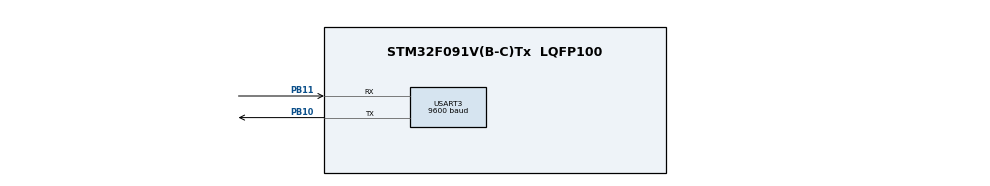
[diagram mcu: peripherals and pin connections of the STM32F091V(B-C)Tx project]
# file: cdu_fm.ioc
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Mcu.Family=STM32F0
Mcu.Name=STM32F091V(B-C)Tx
Mcu.Package=LQFP100
NVIC.USART3_8_IRQn=true\:0\:0\:false\:false\:true\:true\:true\:true
PA13.Mode=Serial_Wire
PA13.Signal=SYS_SWDIO
PA14.Mode=Serial_Wire
PA14.Signal=SYS_SWCLK
PB10.Mode=Asynchronous
PB10.Signal=USART3_TX
PB11.Mode=Asynchronous
PB11.Signal=USART3_RX
ProjectManager.HeapSize=0x200
ProjectManager.StackSize=0x400
ProjectManager.TargetToolchain=STM32CubeIDE
USART3.BaudRate=9600
USART3.VirtualMode-Asynchronous=VM_ASYNC
board=custom

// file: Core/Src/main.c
/* USER CODE BEGIN Header */
/**
  ******************************************************************************
  * @file           : main.c
  * @brief          : Main program body
  ******************************************************************************
  * @attention
  *
  * Copyright (c) 2024 STMicroelectronics.
  * All rights reserved.
  *
  * This software is licensed under terms that can be found in the LICENSE file
  * in the root directory of this software component.
  * If no LICENSE file comes with this software, it is provided AS-IS.
  *
  ******************************************************************************
  */
/* USER CODE END Header */
#include "main.h"

#include "nextionLcd.h"

/* USER CODE BEGIN PTD */

extern returnStatus ret;
extern lcdCmdPage_id page;
extern lcdCmdParam_id param;

/* USER CODE END PTD */

UART_HandleTypeDef huart3;

void SystemClock_Config(void);
static void MX_GPIO_Init(void);
static void MX_USART3_UART_Init(void);

int main(void)
{

  /* MCU Configuration--------------------------------------------------------*/

  /* Reset of all peripherals, Initializes the Flash interface and the Systick. */
  HAL_Init();

  /* Configure the system clock */
  SystemClock_Config();

  /* Initialize all configured peripherals */
  MX_GPIO_Init();
  MX_USART3_UART_Init();
  /* USER CODE BEGIN 2 */

//  if(InitializeLCD(void)){
//	  //lcd initialize successfully
//	  page = lcdPage_nav;
//  }
//  else
//  {
//	  paeg = lcdPage_main;
//  }

  //HAL_Delay(2000);

  mainScreen();

//  if(ChangePage(page))
//  {
//	  for(;;)
//	  {
//		  param = nav_param_afreq;
//		  UpdateParamLCD(param, 112.45);
//
//		  HAL_Delay(1000);
//
//		  param = nav_param_sfreq;
//		  UpdateParamLCD(param, 123.65);
//
//		  HAL_Delay(1000);
//
//		  param = nav_param_afreq;
//		  UpdateParamLCD(param, 345.45);
//
//		  HAL_Delay(1000);
//
//		  param = nav_param_sfreq;
//		  UpdateParamLCD(param, 567.65);
//
//		  HAL_Delay(1000);
//
//		  param = nav_param_vol;
//		  UpdateParamLCD(param, 34);
//
//		  HAL_Delay(1000);
//
//		  param = nav_param_vol;
//		  UpdateParamLCD(param, 5);
//	  }
//  }
  /* USER CODE END 2 */

  /* Infinite loop */
  while (1)
  {

  }
}

void SystemClock_Config(void)
{
  RCC_OscInitTypeDef RCC_OscInitStruct = {0};
  RCC_ClkInitTypeDef RCC_ClkInitStruct = {0};
  RCC_PeriphCLKInitTypeDef PeriphClkInit = {0};

  /** Initializes the RCC Oscillators according to the specified parameters
  * in the RCC_OscInitTypeDef structure.
  */
  RCC_OscInitStruct.OscillatorType = RCC_OSCILLATORTYPE_HSI;
  RCC_OscInitStruct.HSIState = RCC_HSI_ON;
  RCC_OscInitStruct.HSICalibrationValue = RCC_HSICALIBRATION_DEFAULT;
  RCC_OscInitStruct.PLL.PLLState = RCC_PLL_NONE;
  if (HAL_RCC_OscConfig(&RCC_OscInitStruct) != HAL_OK)
  {
    Error_Handler();
  }

  /** Initializes the CPU, AHB and APB buses clocks
  */
  RCC_ClkInitStruct.ClockType = RCC_CLOCKTYPE_HCLK|RCC_CLOCKTYPE_SYSCLK
                              |RCC_CLOCKTYPE_PCLK1;
  RCC_ClkInitStruct.SYSCLKSource = RCC_SYSCLKSOURCE_HSI;
  RCC_ClkInitStruct.AHBCLKDivider = RCC_SYSCLK_DIV1;
  RCC_ClkInitStruct.APB1CLKDivider = RCC_HCLK_DIV1;

  if (HAL_RCC_ClockConfig(&RCC_ClkInitStruct, FLASH_LATENCY_0) != HAL_OK)
  {
    Error_Handler();
  }
  PeriphClkInit.PeriphClockSelection = RCC_PERIPHCLK_USART3;
  PeriphClkInit.Usart3ClockSelection = RCC_USART3CLKSOURCE_PCLK1;
  if (HAL_RCCEx_PeriphCLKConfig(&PeriphClkInit) != HAL_OK)
  {
    Error_Handler();
  }
}

static void MX_USART3_UART_Init(void)
{

  huart3.Instance = USART3;
  huart3.Init.BaudRate = 9600;
  huart3.Init.WordLength = UART_WORDLENGTH_8B;
  huart3.Init.StopBits = UART_STOPBITS_1;
  huart3.Init.Parity = UART_PARITY_NONE;
  huart3.Init.Mode = UART_MODE_TX_RX;
  huart3.Init.HwFlowCtl = UART_HWCONTROL_NONE;
  huart3.Init.OverSampling = UART_OVERSAMPLING_16;
  huart3.Init.OneBitSampling = UART_ONE_BIT_SAMPLE_DISABLE;
  huart3.AdvancedInit.AdvFeatureInit = UART_ADVFEATURE_NO_INIT;
  if (HAL_UART_Init(&huart3) != HAL_OK)
  {
    Error_Handler();
  }

}

static void MX_GPIO_Init(void)
{

  /* GPIO Ports Clock Enable */
  __HAL_RCC_GPIOB_CLK_ENABLE();
  __HAL_RCC_GPIOA_CLK_ENABLE();

}

void Error_Handler(void)
{
  __disable_irq();
  while (1)
  {
  }
}
